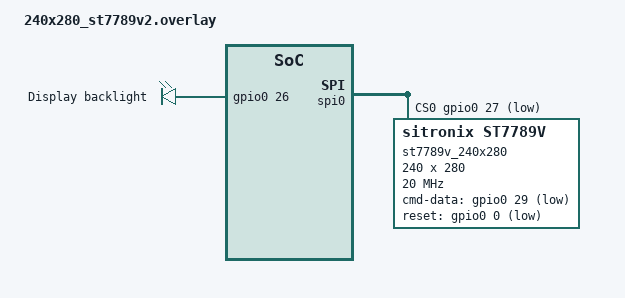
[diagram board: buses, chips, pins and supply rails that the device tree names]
/*
 * Copyright (c) 2019 Jan Van Winkel <jan.van_winkel@dxplore.eu>
 * Copyright (c) 2019 PHYTEC Messtechnik GmbH
 *
 * SPDX-License-Identifier: Apache-2.0
 */

 / {
	chosen {
		zephyr,display = &st7789v_240x280;
	};
	aliases {
		led0 = &led0;
	};

	leds {
		compatible = "gpio-leds";
		led0: led_0 {
			gpios = <&gpio0 26 GPIO_ACTIVE_HIGH>;
			label = "Display backlight";
		};
	};
};

&spi0 {
	status = "okay";
	cs-gpios = <&gpio0 27 GPIO_ACTIVE_LOW>;

	st7789v_240x280: st7789v@0 {
        status = "okay";
		compatible = "sitronix,st7789v";
		spi-max-frequency = <20000000>;
		reg = <0>;
		cmd-data-gpios = <&gpio0 29 GPIO_ACTIVE_LOW>;
		reset-gpios = <&gpio0 0 GPIO_ACTIVE_LOW>;
		width = <240>;
		height = <280>;
		x-offset = <0>;
		y-offset = <20>;
		vcom = <0x19>;
		gctrl = <0x35>;
		vrhs = <0x12>;
		vdvs = <0x20>;
		mdac = <0x00>;
		gamma = <0x01>;
		colmod = <0x05>;
		lcm = <0x2c>;
		porch-param = [0c 0c 00 33 33];
		cmd2en-param = [5a 69 02 01];
		pwctrl1-param = [a4 a1];
		pvgam-param = [D0 04 0D 11 13 2B 3F 54 4C 18 0D 0B 1F 23];
		nvgam-param = [D0 04 0C 11 13 2C 3F 44 51 2F 1F 1F 20 23];
		ram-param = [00 F0];
		rgb-param = [CD 08 14];
	};
};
